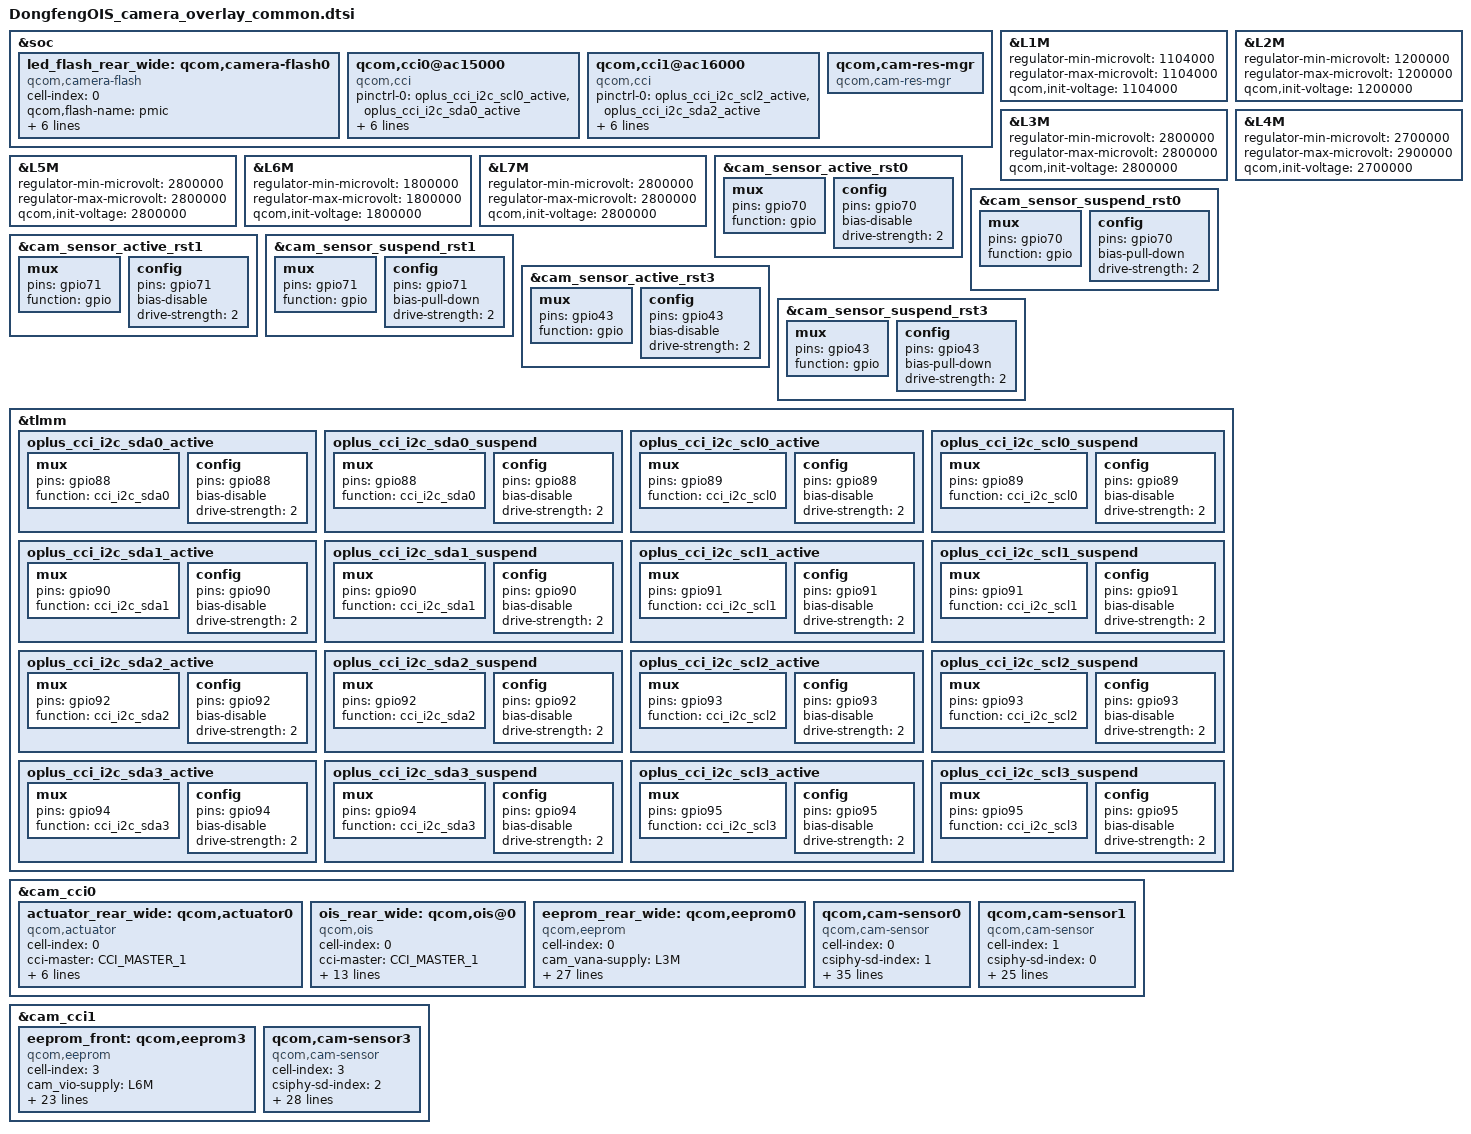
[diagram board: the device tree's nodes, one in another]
#include <dt-bindings/msm-camera.h>

&soc {
	led_flash_rear_wide: qcom,camera-flash0 {
		cell-index = <0>;
		compatible = "qcom,camera-flash";
		qcom,flash-name = "pmic";
		oplus,flash-max-current = <2000>;
		flash-source = <&pmxr2230_flash0 &pmxr2230_flash1 &pmxr2230_flash2>;
		torch-source = <&pmxr2230_torch0 &pmxr2230_torch1 &pmxr2230_torch2>;
		switch-source = <&pmxr2230_switch2>;
		status = "ok";
	};

	qcom,cci0@ac15000 {
		compatible = "qcom,cci", "simple-bus";
		pinctrl-0 = <&oplus_cci_i2c_scl0_active &oplus_cci_i2c_sda0_active>;
		pinctrl-1 = <&oplus_cci_i2c_scl0_suspend &oplus_cci_i2c_sda0_suspend>;
		pinctrl-2 = <&oplus_cci_i2c_scl1_active &oplus_cci_i2c_sda1_active>;
		pinctrl-3 = <&oplus_cci_i2c_scl1_suspend &oplus_cci_i2c_sda1_suspend>;
	};

	qcom,cci1@ac16000 {
		compatible = "qcom,cci", "simple-bus";
		pinctrl-0 = <&oplus_cci_i2c_scl2_active &oplus_cci_i2c_sda2_active>;
		pinctrl-1 = <&oplus_cci_i2c_scl2_suspend &oplus_cci_i2c_sda2_suspend>;
		pinctrl-2 = <&oplus_cci_i2c_scl3_active &oplus_cci_i2c_sda3_active>;
		pinctrl-3 = <&oplus_cci_i2c_scl3_suspend &oplus_cci_i2c_sda3_suspend>;
	};

	qcom,cam-res-mgr {
		compatible = "qcom,cam-res-mgr";
		status = "ok";
	};
};

&L1M {
  regulator-min-microvolt = <1104000>;
  regulator-max-microvolt = <1104000>;
  qcom,init-voltage = <1104000>;
};

&L2M {
  regulator-min-microvolt = <1200000>;
  regulator-max-microvolt = <1200000>;
  qcom,init-voltage = <1200000>;
};

&L3M {
  regulator-min-microvolt = <2800000>;
  regulator-max-microvolt = <2800000>;
  qcom,init-voltage = <2800000>;
};

&L4M {
  regulator-min-microvolt = <2700000>;
  regulator-max-microvolt = <2900000>;
  qcom,init-voltage = <2700000>;
};

&L5M {
  regulator-min-microvolt = <2800000>;
  regulator-max-microvolt = <2800000>;
  qcom,init-voltage = <2800000>;
};

&L6M {
  regulator-min-microvolt = <1800000>;
  regulator-max-microvolt = <1800000>;
  qcom,init-voltage = <1800000>;
};

&L7M {
  regulator-min-microvolt = <2800000>;
  regulator-max-microvolt = <2800000>;
  qcom,init-voltage = <2800000>;
};

&cam_sensor_active_rst0 {
	mux {
		pins = "gpio70";
		function = "gpio";
	};

	config {
		pins = "gpio70";
		bias-disable; /* No PULL */
		drive-strength = <2>; /* 2 MA */
	};
};

&cam_sensor_suspend_rst0 {
	mux {
		pins = "gpio70";
		function = "gpio";
	};

	config {
		pins = "gpio70";
		bias-pull-down; /* PULL DOWN */
		drive-strength = <2>; /* 2 MA */
	};
};

&cam_sensor_active_rst1 {
	mux {
		pins = "gpio71";
		function = "gpio";
	};

	config {
		pins = "gpio71";
		bias-disable; /* No PULL */
		drive-strength = <2>; /* 2 MA */
	};
};

&cam_sensor_suspend_rst1 {
	mux {
		pins = "gpio71";
		function = "gpio";
	};

	config {
		pins = "gpio71";
		bias-pull-down; /* PULL DOWN */
		drive-strength = <2>; /* 2 MA */
	};
};

&cam_sensor_active_rst3 {
	mux {
		pins = "gpio43";
		function = "gpio";
	};

	config {
		pins = "gpio43";
		bias-disable; /* No PULL */
		drive-strength = <2>; /* 2 MA */
	};
};

&cam_sensor_suspend_rst3 {
	mux {
		pins = "gpio43";
		function = "gpio";
	};

	config {
		pins = "gpio43";
		bias-pull-down; /* PULL DOWN */
		drive-strength = <2>; /* 2 MA */
	};
};

&tlmm {
    oplus_cci_i2c_sda0_active: oplus_cci_i2c_sda0_active {
        mux {
            /* CLK, DATA */
            pins = "gpio88";
            function = "cci_i2c_sda0";
        };

        config {
            pins = "gpio88";
            bias-disable; /* DISABLE */
            drive-strength = <2>; /* 2 MA */
        };
    };

    oplus_cci_i2c_sda0_suspend: oplus_cci_i2c_sda0_suspend {
        mux {
            /* CLK, DATA */
            pins = "gpio88";
            function = "cci_i2c_sda0";
        };

        config {
            pins = "gpio88";
            bias-disable; /* DISABLE */
            drive-strength = <2>; /* 2 MA */
        };
    };

    oplus_cci_i2c_scl0_active: oplus_cci_i2c_scl0_active {
        mux {
            /* CLK, DATA */
            pins = "gpio89";
            function = "cci_i2c_scl0";
        };

        config {
            pins = "gpio89";
            bias-disable; /* DISABLE */
            drive-strength = <2>; /* 2 MA */
        };
    };

    oplus_cci_i2c_scl0_suspend: oplus_cci_i2c_scl0_suspend {
        mux {
            /* CLK, DATA */
            pins = "gpio89";
            function = "cci_i2c_scl0";
        };

        config {
            pins = "gpio89";
            bias-disable; /* DISABLE */
            drive-strength = <2>; /* 2 MA */
        };
    };

    oplus_cci_i2c_sda1_active: oplus_cci_i2c_sda1_active {
        mux {
            /* CLK, DATA */
            pins = "gpio90";
            function = "cci_i2c_sda1";
        };

        config {
            pins = "gpio90";
            bias-disable; /* DISABLE */
            drive-strength = <2>; /* 2 MA */
        };
    };

    oplus_cci_i2c_sda1_suspend: oplus_cci_i2c_sda1_suspend {
        mux {
            /* CLK, DATA */
            pins = "gpio90";
            function = "cci_i2c_sda1";
        };

        config {
            pins = "gpio90";
            bias-disable; /* DISABLE */
            drive-strength = <2>; /* 2 MA */
        };
    };

    oplus_cci_i2c_scl1_active: oplus_cci_i2c_scl1_active {
        mux {
            /* CLK, DATA */
            pins = "gpio91";
            function = "cci_i2c_scl1";
        };

        config {
            pins = "gpio91";
            bias-disable; /* DISABLE */
            drive-strength = <2>; /* 2 MA */
        };
    };

    oplus_cci_i2c_scl1_suspend: oplus_cci_i2c_scl1_suspend {
        mux {
            /* CLK, DATA */
            pins = "gpio91";
            function = "cci_i2c_scl1";
        };

        config {
            pins = "gpio91";
            bias-disable; /* DISABLE */
            drive-strength = <2>; /* 2 MA */
        };
    };

    oplus_cci_i2c_sda2_active: oplus_cci_i2c_sda2_active {
        mux {
            /* CLK, DATA */
            pins = "gpio92";
            function = "cci_i2c_sda2";
        };

        config {
            pins = "gpio92";
            bias-disable; /* DISABLE */
            drive-strength = <2>; /* 2 MA */
        };
    };

    oplus_cci_i2c_sda2_suspend: oplus_cci_i2c_sda2_suspend {
        mux {
            /* CLK, DATA */
            pins = "gpio92";
            function = "cci_i2c_sda2";
        };

        config {
            pins = "gpio92";
            bias-disable; /* DISABLE */
            drive-strength = <2>; /* 2 MA */
        };
    };

    oplus_cci_i2c_scl2_active: oplus_cci_i2c_scl2_active {
        mux {
            /* CLK, DATA */
            pins = "gpio93";
            function = "cci_i2c_scl2";
        };

        config {
            pins = "gpio93";
            bias-disable; /* DISABLE */
            drive-strength = <2>; /* 2 MA */
        };
    };

    oplus_cci_i2c_scl2_suspend: oplus_cci_i2c_scl2_suspend {
        mux {
            /* CLK, DATA */
            pins = "gpio93";
            function = "cci_i2c_scl2";
        };

        config {
            pins = "gpio93";
            bias-disable; /* DISABLE */
            drive-strength = <2>; /* 2 MA */
        };
    };

    oplus_cci_i2c_sda3_active: oplus_cci_i2c_sda3_active {
        mux {
            /* CLK, DATA */
            pins = "gpio94";
            function = "cci_i2c_sda3";
        };

        config {
            pins = "gpio94";
            bias-disable; /* DISABLE */
            drive-strength = <2>; /* 2 MA */
        };
    };

    oplus_cci_i2c_sda3_suspend: oplus_cci_i2c_sda3_suspend {
        mux {
            /* CLK, DATA */
            pins = "gpio94";
            function = "cci_i2c_sda3";
        };

        config {
            pins = "gpio94";
            bias-disable; /* DISABLE */
            drive-strength = <2>; /* 2 MA */
        };
    };

    oplus_cci_i2c_scl3_active: oplus_cci_i2c_scl3_active {
        mux {
            /* CLK, DATA */
            pins = "gpio95";
            function = "cci_i2c_scl3";
        };

        config {
            pins = "gpio95";
            bias-disable; /* DISABLE */
            drive-strength = <2>; /* 2 MA */
        };
    };

    oplus_cci_i2c_scl3_suspend: oplus_cci_i2c_scl3_suspend {
        mux {
            /* CLK, DATA */
            pins = "gpio95";
            function = "cci_i2c_scl3";
        };

        config {
            pins = "gpio95";
            bias-disable; /* DISABLE */
            drive-strength = <2>; /* 2 MA */
        };
    };
};

&cam_cci0 {

    //main camera
	actuator_rear_wide: qcom,actuator0 {
		cell-index = <0>;
		compatible = "qcom,actuator";
		cci-master = <CCI_MASTER_1>;
		cam_vaf-supply = <&L7M>;
		regulator-names = "cam_vaf";
		rgltr-cntrl-support;
		rgltr-min-voltage = <2800000>;
		rgltr-max-voltage = <2800000>;
		rgltr-load-current = <300000>;
		//is_update_pid;
		//actuator,name = "gt9772";
		status = "ok";
	};

    //main camera
	ois_rear_wide: qcom,ois@0{
		cell-index = <0>;
		compatible = "qcom,ois";
		cci-master = <CCI_MASTER_1>;
		cam_vio-supply = <&L6M>;
		cam_vaf-supply = <&L7M>;
		regulator-names = "cam_vio", "cam_vaf";
		rgltr-cntrl-support;
		rgltr-min-voltage = <1800000 2800000>;
		rgltr-max-voltage = <1800000 2800000>;
		rgltr-load-current = <150000 300000>;
		ois_gyro,position=<3>;
		ois_gyro,type=<3>;
		ois,type=<0>;
		//ois,name="JD5516WE4";
		ois_module,vendor=<1>;
		ois_actuator,vednor=<2>;
		ois,fw=<1>;
		status = "ok";
	};

    //main camera
	eeprom_rear_wide: qcom,eeprom0 {
		cell-index = <0>;
		compatible = "qcom,eeprom";
		cam_vana-supply = <&L3M>;
		cam_vdig-supply = <&L2M>;
		cam_vio-supply = <&L6M>;
		cam_vaf-supply = <&L7M>;
		cam_clk-supply = <&cam_cc_camss_top_gdsc>;
		regulator-names = "cam_vana", "cam_vdig", "cam_vio", "cam_vaf", "cam_clk";
		rgltr-cntrl-support;
		rgltr-min-voltage = <2800000 1200000 1800000 2800000 0>;
		rgltr-max-voltage = <2800000 1200000 1800000 2800000 0>;
		rgltr-load-current = <300000 1200000 150000 300000 0>;
		gpio-no-mux = <0>;
		pinctrl-names = "cam_default", "cam_suspend";
		pinctrl-0 = <&cam_sensor_mclk1_active
			&cam_sensor_active_rst1>;
		pinctrl-1 = <&cam_sensor_mclk1_suspend
			&cam_sensor_suspend_rst1>;
		gpios = <&tlmm 84 0>,
			<&tlmm 71 0>;
		gpio-reset = <1>;
		gpio-req-tbl-num = <0 1>;
		gpio-req-tbl-flags = <1 0>;
		gpio-req-tbl-label = "CAMIF_MCLK1",
					"CAM_RESET1";
		cci-master = <CCI_MASTER_1>;
		clocks = <&camcc CAM_CC_MCLK1_CLK>;
		clock-names = "cam_clk";
		clock-cntl-level = "nominal";
		clock-rates = <19200000>;
		status = "ok";
	};


    //main camera
	qcom,cam-sensor0 {
		cell-index = <0>;
		compatible = "qcom,cam-sensor";
		csiphy-sd-index = <1>;
		sensor-position-roll = <90>;
		sensor-position-pitch = <0>;
		sensor-position-yaw = <180>;
		eeprom-src = <&eeprom_rear_wide>;
		actuator-src = <&actuator_rear_wide>;
		ois-src = <&ois_rear_wide>;
		led-flash-src = <&led_flash_rear_wide>;
		cam_vana-supply = <&L3M>;
		cam_vdig-supply = <&L2M>;
		cam_vio-supply = <&L6M>;
		cam_vaf-supply = <&L7M>;
		cam_clk-supply = <&cam_cc_camss_top_gdsc>;
		regulator-names = "cam_vana", "cam_vdig", "cam_vio", "cam_vaf", "cam_clk";
		rgltr-cntrl-support;
		rgltr-min-voltage = <2800000 1200000 1800000 2800000 0>;
		rgltr-max-voltage = <2800000 1200000 1800000 2800000 0>;
		rgltr-load-current = <300000 1200000 150000 300000 0>;
		gpio-no-mux = <0>;
		pinctrl-names = "cam_default", "cam_suspend";
		pinctrl-0 = <&cam_sensor_mclk1_active
			&cam_sensor_active_rst1>;
		pinctrl-1 = <&cam_sensor_mclk1_suspend
			&cam_sensor_suspend_rst1>;
		gpios = <&tlmm 84 0>,
			<&tlmm 71 0>;
		gpio-reset = <1>;
		gpio-req-tbl-num = <0 1>;
		gpio-req-tbl-flags = <1 0>;
		gpio-req-tbl-label = "CAMIF_MCLK1",
					"CAM_RESET1";
		cci-master = <CCI_MASTER_1>;
		clocks = <&camcc CAM_CC_MCLK1_CLK>;
		clock-names = "cam_clk";
		clock-cntl-level = "nominal";
		clock-rates = <19200000>;
		status = "ok";
	};

    //2M camera
	qcom,cam-sensor1 {
		cell-index = <1>;
		compatible = "qcom,cam-sensor";
		csiphy-sd-index = <0>;
		sensor-position-roll = <90>;
		sensor-position-pitch = <0>;
		sensor-position-yaw = <180>;
		//led-flash-src = <&led_flash_rear_ultrawide>;
		cam_vio-supply = <&L6M>;
		cam_vana-supply = <&L4M>;
		cam_clk-supply = <&cam_cc_camss_top_gdsc>;
		regulator-names = "cam_vio", "cam_vana", "cam_clk";
		rgltr-cntrl-support;
		rgltr-min-voltage = <1800000 2800000 0>;
		rgltr-max-voltage = <1800000 2800000 0>;
		rgltr-load-current = <150000 300000 0>;
		gpio-no-mux = <0>;
		pinctrl-names = "cam_default", "cam_suspend";
		pinctrl-0 = <&cam_sensor_mclk0_active
				 &cam_sensor_active_rst0>;
		pinctrl-1 = <&cam_sensor_mclk0_suspend
				 &cam_sensor_suspend_rst0>;
		gpios = <&tlmm 83 0>,
			<&tlmm 70 0>;
		gpio-reset = <1>;
		gpio-req-tbl-num = <0 1>;
		gpio-req-tbl-flags = <1 0>;
		gpio-req-tbl-label = "CAMIF_MCLK0",
					"CAM_RESET0";
		cci-master = <CCI_MASTER_0>;
		clocks = <&camcc CAM_CC_MCLK0_CLK>;
		clock-names = "cam_clk";
		clock-cntl-level = "nominal";
		clock-rates = <19200000>;
		status = "ok";
	};
};

&cam_cci1 {
    //front camera
	eeprom_front: qcom,eeprom3 {
		cell-index = <3>;
		compatible = "qcom,eeprom";
		cam_vio-supply = <&L6M>;
		cam_vana-supply = <&L5M>;
		cam_vdig-supply = <&L1M>;
		cam_clk-supply = <&cam_cc_camss_top_gdsc>;
		regulator-names = "cam_vio", "cam_vana", "cam_vdig", "cam_clk";
		rgltr-cntrl-support;
		rgltr-min-voltage = <1800000 2800000 1104000 0>;
		rgltr-max-voltage = <1800000 2800000 1104000 0>;
		rgltr-load-current = <150000 300000 1500000 0>;
		gpio-no-mux = <0>;
		pinctrl-names = "cam_default", "cam_suspend";
		pinctrl-0 = <&cam_sensor_mclk3_active
				 &cam_sensor_active_rst3>;
		pinctrl-1 = <&cam_sensor_mclk3_suspend
				 &cam_sensor_suspend_rst3>;
		gpios = <&tlmm 86 0>,
			<&tlmm 43 0>;
		gpio-reset = <1>;
		gpio-req-tbl-num = <0 1>;
		gpio-req-tbl-flags = <1 0>;
		gpio-req-tbl-label = "CAMIF_MCLK3",
					"CAM_RESET3";
		cci-master = <CCI_MASTER_1>;
		clocks = <&camcc CAM_CC_MCLK3_CLK>;
		clock-names = "cam_clk";
		clock-cntl-level = "nominal";
		clock-rates = <19200000>;
		status = "ok";
	};

    //front camera
	qcom,cam-sensor3 {
		cell-index = <3>;
		compatible = "qcom,cam-sensor";
		csiphy-sd-index = <2>;
		sensor-position-roll = <90>;
		sensor-position-pitch = <0>;
		sensor-position-yaw = <180>;
		eeprom-src = <&eeprom_front>;
		cam_vio-supply = <&L6M>;
		cam_vana-supply = <&L5M>;
		cam_vdig-supply = <&L1M>;
		cam_clk-supply = <&cam_cc_camss_top_gdsc>;
		regulator-names = "cam_vio", "cam_vana", "cam_vdig", "cam_clk";
		rgltr-cntrl-support;
		rgltr-min-voltage = <1800000 2800000 1104000 0>;
		rgltr-max-voltage = <1800000 2800000 1104000 0>;
		rgltr-load-current = <150000 300000 1500000 0>;
		gpio-no-mux = <0>;
		pinctrl-names = "cam_default", "cam_suspend";
		pinctrl-0 = <&cam_sensor_mclk3_active
				 &cam_sensor_active_rst3>;
		pinctrl-1 = <&cam_sensor_mclk3_suspend
				 &cam_sensor_suspend_rst3>;
		gpios = <&tlmm 86 0>,
			<&tlmm 43 0>;
		gpio-reset = <1>;
		gpio-req-tbl-num = <0 1>;
		gpio-req-tbl-flags = <1 0>;
		gpio-req-tbl-label = "CAMIF_MCLK3",
					"CAM_RESET3";
		cci-master = <CCI_MASTER_1>;
		clocks = <&camcc CAM_CC_MCLK3_CLK>;
		clock-names = "cam_clk";
		clock-cntl-level = "nominal";
		clock-rates = <19200000>;
		status = "ok";
	};
};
